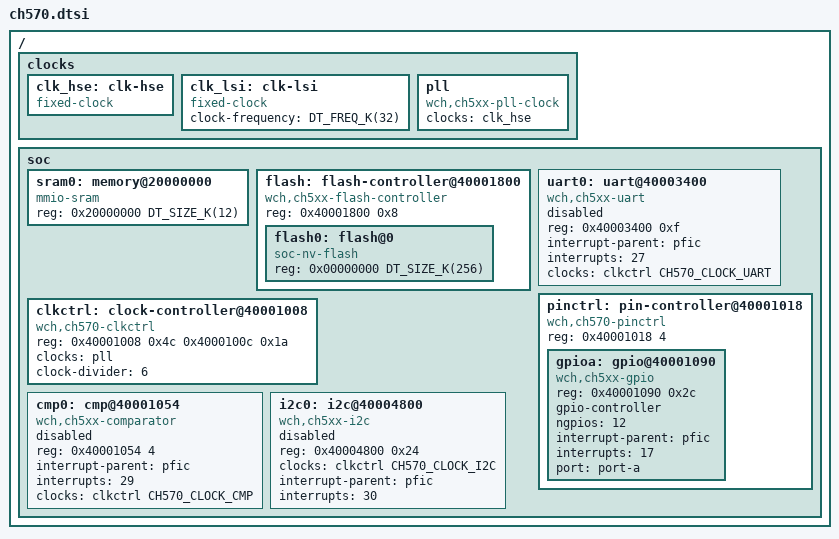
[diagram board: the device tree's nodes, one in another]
/*
 * SPDX-FileCopyrightText: 2026 SMILE (smile.eu)
 *
 * SPDX-License-Identifier: Apache-2.0
 */

#include <freq.h>
#include <mem.h>
#include <wch/qingke-v3c.dtsi>
#include <zephyr/dt-bindings/clock/ch570-clock.h>

/ {
	clocks {
		clk_hse: clk-hse {
			#clock-cells = <0>;
			compatible = "fixed-clock";
			status = "okay";
		};

		clk_lsi: clk-lsi {
			#clock-cells = <0>;
			compatible = "fixed-clock";
			clock-frequency = <DT_FREQ_K(32)>;
			status = "okay";
		};

		pll: pll {
			#clock-cells = <0>;
			compatible = "wch,ch5xx-pll-clock";
			clocks = <&clk_hse>;
			status = "okay";
		};
	};

	soc {
		sram0: memory@20000000 {
			compatible = "mmio-sram";
			reg = <0x20000000 DT_SIZE_K(12)>;
		};

		flash: flash-controller@40001800 {
			compatible = "wch,ch5xx-flash-controller";
			reg = <0x40001800 0x8>;
			ranges;

			#address-cells = <1>;
			#size-cells = <1>;

			flash0: flash@0 {
				compatible = "soc-nv-flash";
				ranges = <0x0 0x00000000 DT_SIZE_K(256)>;
				reg = <0x00000000 DT_SIZE_K(256)>;

				#address-cells = <1>;
				#size-cells = <1>;
			};
		};

		uart0: uart@40003400 {
			compatible = "wch,ch5xx-uart";
			reg = <0x40003400 0xf>;
			interrupt-parent = <&pfic>;
			interrupts = <27>;
			clocks = <&clkctrl CH570_CLOCK_UART>;
			status = "disabled";
		};

		pinctrl: pin-controller@40001018 {
			compatible = "wch,ch570-pinctrl";
			reg = <0x40001018 4>;
			#address-cells = <1>;
			#size-cells = <1>;

			gpioa: gpio@40001090 {
				compatible = "wch,ch5xx-gpio";
				reg = <0x40001090 0x2c>;
				gpio-controller;
				#gpio-cells = <2>;
				ngpios = <12>;
				interrupt-parent = <&pfic>;
				interrupts = <17>;
				port = "port-a";
			};
		};

		clkctrl: clock-controller@40001008 {
			compatible = "wch,ch570-clkctrl";
			reg = <0x40001008 0x4c 0x4000100c 0x1a>;
			reg-names = "config_ctrl", "sleep_ctrl";
			clocks = <&pll>;
			#clock-cells = <1>;
			clock-divider = <6>; /* 100 MHz max */
			status = "okay";
		};

		cmp0: cmp@40001054 {
			compatible = "wch,ch5xx-comparator";
			reg = <0x40001054 4>;
			interrupt-parent = <&pfic>;
			interrupts = <29>;
			clocks = <&clkctrl CH570_CLOCK_CMP>;
			status = "disabled";
		};

		i2c0: i2c@40004800 {
			compatible = "wch,ch5xx-i2c";
			reg = <0x40004800 0x24>;
			clocks = <&clkctrl CH570_CLOCK_I2C>;
			interrupt-parent = <&pfic>;
			interrupts = <30>;
			status = "disabled";
			#address-cells = <1>;
			#size-cells = <0>;
		};
	};
};
